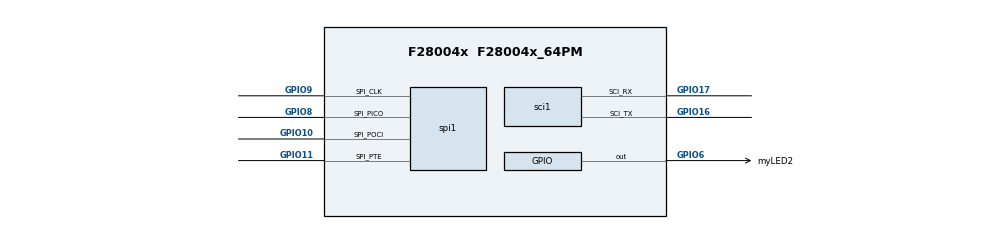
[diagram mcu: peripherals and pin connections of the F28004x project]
/**
 * @cliArgs --device "F28004x" --part "F28004x_64PM" --package "F28004x_64PM" --context "system" --product "C2000WARE@6.00.00.00"
 * @versions {"tool":"1.25.0+4268"}
 */

/**
 * Import the modules used in this configuration.
 */
const led            = scripting.addModule("/driverlib/board_components/led", {}, false);
const led1           = led.addInstance();
const cputimer       = scripting.addModule("/driverlib/cputimer.js", {}, false);
const cputimer1      = cputimer.addInstance();
const cputimer2      = cputimer.addInstance();
const device_support = scripting.addModule("/driverlib/device_support.js");
const sci            = scripting.addModule("/driverlib/sci.js", {}, false);
const sci1           = sci.addInstance();
const spi            = scripting.addModule("/driverlib/spi.js", {}, false);
const spi1           = spi.addInstance();
const FREERTOS       = scripting.addModule("/kernel/freertos_tool/FREERTOS", {}, false);
const FREERTOS1      = FREERTOS.addInstance();

/**
 * Write custom configuration values to the imported modules.
 */
led1.$name                  = "myLED2";
led1.gpio.writeInitialValue = true;
led1.gpio.initialValue      = 1;
led1.gpio.gpioPin.$assign   = "GPIO6";

const divider1       = system.clockTree["CLBCLKDIV"];
divider1.divideValue = 4;

const divider2       = system.clockTree["LOSPCP"];
divider2.divideValue = 1;

cputimer1.$name                     = "timer1";
cputimer1.cputimerBase              = "CPUTIMER1_BASE";
cputimer1.enableInterrupt           = true;
cputimer1.registerInterrupts        = true;
cputimer1.startTimer                = true;
cputimer1.timerPeriod               = 100000;
cputimer1.timerInt.interruptHandler = "timer1_ISR";
cputimer1.timerInt.enableInterrupt  = true;

cputimer2.$name                     = "timer0";
cputimer2.enableInterrupt           = true;
cputimer2.registerInterrupts        = true;
cputimer2.startTimer                = true;
cputimer2.timerPeriod               = 10000000;
cputimer2.timerInt.enableInterrupt  = true;
cputimer2.timerInt.interruptHandler = "timer0_ISR";

sci1.$name                      = "mySCI0";
sci1.selectRegisteredInterrupts = ["registerRxInt","registerTxInt"];
sci1.enabledFIFOInterrupts      = ["SCI_INT_TXFF"];
sci1.sci.sci_rxPin.$assign      = "GPIO17";
sci1.sci.sci_txPin.$assign      = "GPIO16";
sci1.rxQual.$name               = "myGPIOQUAL2";
sci1.txQual.$name               = "myGPIOQUAL3";
sci1.sciTXInt.enableInterrupt   = true;

spi1.$name                    = "mySPI0";
spi1.registerInterrupts       = true;
spi1.enabledFIFOInterrupts    = ["SPI_INT_RXFF","SPI_INT_TXFF"];
spi1.mode                     = "SPI_MODE_CONTROLLER";
spi1.rxFifo                   = "SPI_FIFO_RX1";
spi1.spi.$assign              = "SPIA";
spi1.spi.spi_picoPin.$assign  = "GPIO8";
spi1.spi.spi_pociPin.$assign  = "GPIO10";
spi1.spi.spi_clkPin.$assign   = "GPIO9";
spi1.spi.spi_ptePin.$assign   = "GPIO11";
spi1.picoQual.$name           = "myGPIOQUAL0";
spi1.pociQual.$name           = "myGPIOQUAL1";
spi1.clkQual.$name            = "myGPIOQUAL4";
spi1.pteQual.$name            = "myGPIOQUAL5";
spi1.spiRXInt.enableInterrupt = true;
spi1.spiTXInt.enableInterrupt = true;

FREERTOS1.$name                       = "myFREERTOS0";
FREERTOS1.MINIMAL_STACK_SIZE          = 256;
FREERTOS1.USE_MUTEXES                 = true;
FREERTOS1.USE_RECURSIVE_MUTEXES       = true;
FREERTOS1.USE_COUNTING_SEMAPHORES     = true;
FREERTOS1.vTaskSuspend                = false;
FREERTOS1.uxTaskGetStackHighWaterMark = true;
FREERTOS1.CHECK_FOR_STACK_OVERFLOW    = 2;
FREERTOS1.tasks.create(4);
FREERTOS1.tasks[0].$name              = "myTask0";
FREERTOS1.tasks[0].taskPointer        = "myTask0_func";
FREERTOS1.tasks[0].taskStackSize      = 512;
FREERTOS1.tasks[1].$name              = "LOG_Task";
FREERTOS1.tasks[1].taskPointer        = "LOG_Task_Func";
FREERTOS1.tasks[1].taskStackSize      = 2500;
FREERTOS1.tasks[2].$name              = "SCI_RX_Task";
FREERTOS1.tasks[2].taskPointer        = "SCI_RX_Task_Func";
FREERTOS1.tasks[3].$name              = "PROTO_Task";
FREERTOS1.tasks[3].taskPointer        = "PROTO_Task_Func";
FREERTOS1.tasks[3].taskStackSize      = 512;
FREERTOS1.semaphores.create(4);
FREERTOS1.semaphores[0].$name         = "TimeBase_Semaphore";
FREERTOS1.semaphores[1].$name         = "SCI0Tx_Semaphore";
FREERTOS1.semaphores[2].$name         = "SPI0Tx_Semaphore";
FREERTOS1.semaphores[3].$name         = "PROTO_ACK";
FREERTOS1.queues.create(1);
FREERTOS1.queues[0].$name             = "APP_LOG_Queue";
FREERTOS1.queues[0].queueItemSize     = "16";
FREERTOS1.queues[0].queueLength       = 50;

/**
 * Pinmux solution for unlocked pins/peripherals. This ensures that minor changes to the automatic solver in a future
 * version of the tool will not impact the pinmux you originally saw.  These lines can be completely deleted in order to
 * re-solve from scratch.
 */
sci1.sci.$suggestSolution = "SCIA";
